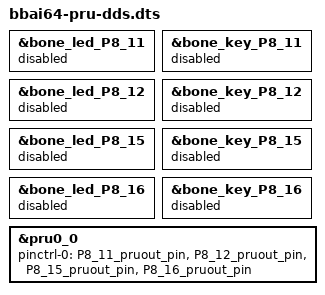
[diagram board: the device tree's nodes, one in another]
/dts-v1/;
/plugin/;

/* Disable default kernel-level device mappings to free the pins */
&bone_led_P8_11 { status = "disabled"; };
&bone_key_P8_11 { status = "disabled"; };

&bone_led_P8_12 { status = "disabled"; };
&bone_key_P8_12 { status = "disabled"; };

&bone_led_P8_15 { status = "disabled"; };
&bone_key_P8_15 { status = "disabled"; };

&bone_led_P8_16 { status = "disabled"; };
&bone_key_P8_16 { status = "disabled"; };

/* Map all four pins to ICSSG0 PRU0 as general purpose outputs */
&pru0_0 {
    pinctrl-names = "default";
    pinctrl-0 = <
        &P8_11_pruout_pin
        &P8_12_pruout_pin
        &P8_15_pruout_pin
        &P8_16_pruout_pin
    >;
};
